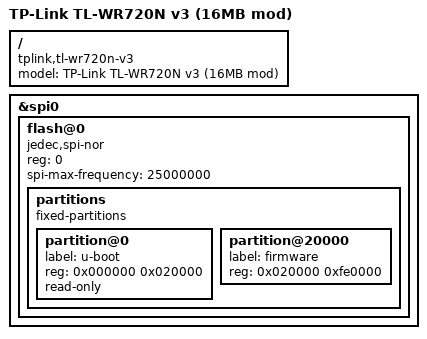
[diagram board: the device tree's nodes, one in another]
/dts-v1/;

#include "ar9331_tplink_tl-wr710n-8m.dtsi"

/ {
    compatible = "tplink,tl-wr720n-v3", "qca,ar9331";
    model = "TP-Link TL-WR720N v3 (16MB mod)";
};

&spi0 {
    flash@0 {
        compatible = "jedec,spi-nor";
        reg = <0>;
        spi-max-frequency = <25000000>;

        partitions {
            compatible = "fixed-partitions";
            #address-cells = <1>;
            #size-cells = <1>;

            partition@0 {
                label = "u-boot";
                reg = <0x000000 0x020000>;
                read-only;
            };

            partition@20000 {
                label = "firmware";
                reg = <0x020000 0xfe0000>;
            };
        };
    };
};
